# ATtiny1634 register map
Vendor: Atmel; File version: 1.0
CPU: other r0p0, little endian, no MPU, no FPU, 4 interrupt priority bits
Registers are 8-bit, read-write, reset 0x0 unless marked. A register's access mark holds for its fields unless they carry their own. Offsets are from the block's base; lines under a group give offsets from that group; [hi:lo] are bit positions; {n}, {i} and the like mark numbered series; 'fields as' and 'values as' point back to an identical list; <NAME> marks a mode.

## Memory map
0x00800000 FUSE size 0x3 — Fuses
0x00800000 LOCKBIT size 0x1 — Lockbits
0x00800020 ADC blocks up to offset 0x43 — Analog-to-Digital Converter
0x00800025 AC size 0x2 — Analog Comparator
0x00800027 PORTC blocks up to offset 0xD — I/O Port
0x0080002B PORTB blocks up to offset 0x9 — I/O Port
0x0080002F PORTA size 0x5 — I/O Port
0x00800034 CPU blocks up to offset 0x33 — CPU Registers
0x00800037 TC0 blocks up to offset 0x31 — Timer/Counter, 8-bit
0x0080003C EEPROM size 0x4
0x00800040 USART0 size 0x7 — USART
0x00800047 EXINT blocks up to offset 0x16 — External Interrupts
0x0080004A USI size 0x4 — Universal Serial Interface
0x00800050 WDT size 0x1 — Watchdog Timer
0x00800059 TC1 blocks up to offset 0x1A — Timer/Counter, 16-bit
0x00800073 USART1 size 0x7 — USART
0x0080007A TWI size 0x6 — Two Wire Serial Interface

## Interrupts
0 RESET (CPU) — External Pin, Power-on Reset, Brown-out Reset and Watchdog Reset
1 INT0 (CPU) — External Interrupt Request 0
2 PCINT0 (CPU) — Pin Change Interrupt Request 0
3 PCINT1 (CPU) — Pin Change Interrupt Request 1
4 PCINT2 (CPU) — Pin Change Interrupt Request 2
5 WDT (CPU) — Watchdog Time-out Interrupt
6 TIMER1_CAPT_CAPT (CPU) — Timer/Counter1 Capture Event
7 TIMER1_COMPA_COMPA (CPU) — Timer/Counter1 Compare Match A
8 TIMER1_COMPB_COMPB (CPU) — Timer/Counter1 Compare Match B
9 TIMER1_OVF_OVF (CPU) — Timer/Counter1 Overflow
10 TIMER0_COMPA_COMPA (CPU) — TimerCounter0 Compare Match A
11 TIMER0_COMPB_COMPB (CPU) — TimerCounter0 Compare Match B
12 TIMER0_OVF_OVF (CPU) — Timer/Counter0 Overflow
13 ANA_COMP (CPU) — Analog Comparator
14 ADC_READY (CPU) — ADC Conversion Complete
15 USART0_START_RXS (CPU) — USART0, Start
16 USART0_RX_RXC (CPU) — USART0, Rx Complete
17 USART0_UDRE_DRE (CPU) — USART0 Data Register Empty
18 USART0_TX_TXC (CPU) — USART0, Tx Complete
19 USART1_START_RXS (CPU) — USART1, Start
20 USART1_RX_RXC (CPU) — USART1, Rx Complete
21 USART1_UDRE_DRE (CPU) — USART1 Data Register Empty
22 USART1_TX_TXC (CPU) — USART1, Tx Complete
23 USI_START_STR (CPU) — USI Start Condition
24 USI_OVERFLOW_OVF (CPU) — USI Overflow
25 TWI_SLAVE_TWI (CPU) — Two-wire Serial Interface
26 EE_RDY (CPU) — EEPROM Ready
27 QTRIP (CPU) — Touch Sensing

## AC — Analog Comparator
Base 0x00800025
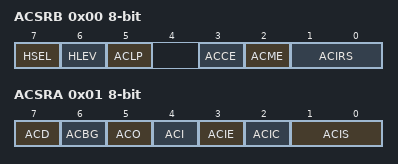
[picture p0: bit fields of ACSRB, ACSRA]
0x00 ACSRB — Analog Comparator Control And Status Register B
  [7] HSEL — Hysteresis Select
  [6] HLEV — Hysteresis Level
  [5] ACLP
  [3] ACCE
  [2] ACME — Analog Comparator Multiplexer Enable
  [1:0] ACIRS
0x01 ACSRA — Analog Comparator Control And Status Register A
  [7] ACD — Analog Comparator Disable
  [6] ACBG — Analog Comparator Bandgap Select
  [5] ACO — Analog Compare Output
  [4] ACI — Analog Comparator Interrupt Flag
  [3] ACIE — Analog Comparator Interrupt Enable
  [2] ACIC — Analog Comparator Input Capture Enable
  [1:0] ACIS — Analog Comparator Interrupt Mode Select bits
    0=INTERRUPT_ON_TOGGLE; 2=INTERRUPT_ON_FALLING_EDGE; 3=INTERRUPT_ON_RISING_EDGE

## ADC — Analog-to-Digital Converter
Base 0x00800020
0x00 ADC 16-bit (reset mask 0xFF) — ADC Data Register Bytes
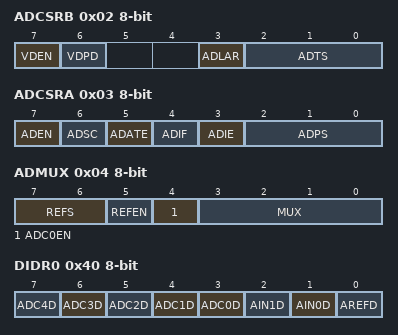
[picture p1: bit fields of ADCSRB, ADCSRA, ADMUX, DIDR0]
0x02 ADCSRB — ADC Control and Status Register B
  [7] VDEN
  [6] VDPD
  [3] ADLAR
  [2:0] ADTS — ADC Auto Trigger Sources
    0=FREE_RUNNING_MODE; 1=ANALOG_COMPARATOR; 2=EXTERNAL_INTERRUPT_REQUEST_0; 3=TIMER_COUNTER0_COMPARE_MATCH_A; 4=TIMER_COUNTER0_OVERFLOW; 5=TIMER_COUNTER1_COMPARE_MATCH_B; 6=TIMER_COUNTER1_OVERFLOW; 7=TIMER_COUNTER1_CAPTURE_EVENT
0x03 ADCSRA — The ADC Control and Status register (read-only for debugger)
  [7] ADEN — ADC Enable
  [6] ADSC — ADC Start Conversion
  [5] ADATE — ADC Auto Trigger Enable
  [4] ADIF — ADC Interrupt Flag
  [3] ADIE — ADC Interrupt Enable
  [2:0] ADPS — ADC Prescaler Select Bits
    1=2; 2=4; 3=8; 4=16; 5=32; 6=64; 7=128
0x04 ADMUX — The ADC multiplexer Selection Register
  [7:6] REFS — Reference Selection Bit
  [5] REFEN
  [4] ADC0EN
  [3:0] MUX — Analog Channel and Gain Selection Bits
0x40 DIDR0 — Digital Input Disable Register 0
  [n+3] ADC{n}D (n=1..4) — ADC{n} Digital input Disable
  [3] ADC0D — ADC0 Digital Input Disable
  [2] AIN1D — AIN1 Digital input Disable
  [1] AIN0D — AIN0 Digital input Disable
  [0] AREFD — AREF Digital input Disable
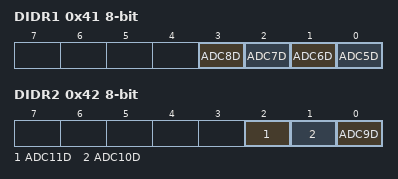
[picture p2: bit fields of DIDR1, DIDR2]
0x41 DIDR1 — Digital Input Disable Register 1
  [3] ADC8D — ADC8 Digital Input Disable
  [2] ADC7D — ADC7 Digital input Disable
  [1] ADC6D — ADC6 Digital input Disable
  [0] ADC5D — ADC5 Digital input Disable
0x42 DIDR2 — Digital Input Disable Register 2
  [2] ADC11D — ADC11 Digital input Disable
  [1] ADC10D — ADC10 Digital input Disable
  [0] ADC9D — ADC9 Digital input Disable
